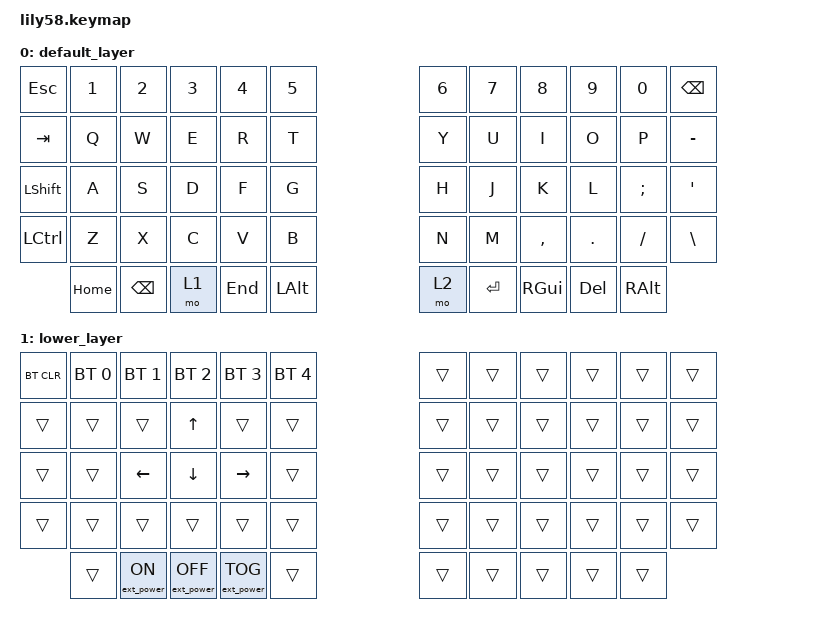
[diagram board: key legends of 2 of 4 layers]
#include <behaviors.dtsi>
#include <dt-bindings/zmk/keys.h>
#include <dt-bindings/zmk/bt.h>
#include <dt-bindings/zmk/outputs.h>
#include <dt-bindings/zmk/mouse.h>
#include <dt-bindings/zmk/ext_power.h>

#define DEFAULT 0
#define LOWER 1
#define RAISE 2

/ {
    keymap {
        compatible = "zmk,keymap";

        default_layer {
// ------------------------------------------------------------------------------------------------------------
// |  ESC  |  1  |  2  |  3   |  4   |  5   |                   |  6   |  7    |  8    |  9   |   0   |  BKSP |
// |  TAB  |  Q  |  W  |  E   |  R   |  T   |                   |  Y   |  U    |  I    |  O   |   P   |   -   |
// | SHIFT |  A  |  S  |  D   |  F   |  G   |                   |  H   |  J    |  K    |  L   |   ;   |   '   |
// | CTRL  |  Z  |  X  |  C   |  V   |  B   |                   |  N   |  M    |  ,    |  .   |   /   |   \   |
//                     | HOME | END  | LALT |                   | RAISE| ENTR  | RGUI|
//                            | BKSP | LOWER|                   | DEL  | ALT |
            bindings = <
&kp ESC   &kp N1    &kp N2   &kp N3    &kp N4    &kp N5                    &kp N6    &kp N7   &kp N8    &kp N9    &kp N0   &kp BSPC
&kp TAB   &kp Q     &kp W    &kp E     &kp R     &kp T                     &kp Y     &kp U    &kp I     &kp O     &kp P    &kp MINUS
&kp LSHFT &kp A     &kp S    &kp D     &kp F     &kp G                     &kp H     &kp J    &kp K     &kp L     &kp SEMI &kp SQT
&kp LCTRL &kp Z     &kp X    &kp C     &kp V     &kp B                     &kp N     &kp M    &kp COMMA &kp DOT   &kp FSLH &kp BSLH
          &kp HOME  &kp BKSP &mo 1    &kp END   &kp LALT                  &mo 2     &kp ENTER &kp RGUI &kp DEL   &kp RALT
            >;
        };

        lower_layer {
            bindings = <
&bt BT_CLR &bt BT_SEL 0 &bt BT_SEL 1  &bt BT_SEL 2 &bt BT_SEL 3 &bt BT_SEL 4                   &trans  &trans  &trans &trans &trans &trans
&trans    &trans    &trans    &kp UP   &trans    &trans                   &trans  &trans  &trans &trans &trans &trans
&trans    &trans    &kp LEFT  &kp DOWN &kp RIGHT &trans                   &trans  &trans  &trans &trans &trans &trans
&trans    &trans    &trans    &trans   &trans    &trans                   &trans  &trans  &trans &trans &trans &trans
&trans    &ext_power EP_ON &ext_power EP_OFF    &ext_power EP_TOG   &trans                             &trans  &trans  &trans &trans &trans
            >;
        };

        raise_layer {
            bindings = <
    &kp F1    &kp F2  &kp F3    &kp F4    &kp F5                        &kp F6     &kp F7    &kp F8      &kp F9    &kp F10
    &kp N1    &kp N2  &kp N3    &kp N4    &kp N5                        &kp N6     &kp N7    &kp N8      &kp N9    &kp N0
    &kp EXCL  &kp AT  &kp HASH  &kp DLLR  &kp PRCNT                     &kp CARET  &kp AMPS  &kp ASTRK   &kp LPAR  &kp RPAR
              &kp F11 &kp F12                                                                &trans      &trans
                                &trans    &trans                        &trans     &trans
                                          &trans    &trans    &trans    &trans
                                          &trans    &trans    &trans    &trans
            >;
        };
    adjust_layer {
            bindings = <
        &kp F1        &kp F2       &kp F3       &kp F4        &kp F5           &kp F6  &kp F7  &kp F8   &kp F9   &kp F10
                &out OUT_BLE  &bt BT_SEL 0 &bt BT_SEL 1 &bt BT_SEL 2  &bt BT_SEL 3     &none   &none   &none    &kp F11  &kp F12
                &out OUT_USB  &none        &none        &none         &none            &none   &none   &none    &none    &none
                              &bt BT_CLR   &bt BT_CLR_ALL                                              &none    &none
                                                      &none &none                      &none &none
                                                      &none &none                      &none &none
                                                      &none &none                      &none &none
            >;
        };
    };
};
